AUTOSAR XML (schema 4-0-3)
standard types defined: Boolean, UInt16, UInt8
package /AUTOSAR_Platform/DataConstrs
  range DC_Boolean: raw 0..1
  range DC_UInt16: raw 0..65535
  range DC_UInt8: raw 0..255
package /PATAC/MSM/ComponentTypes
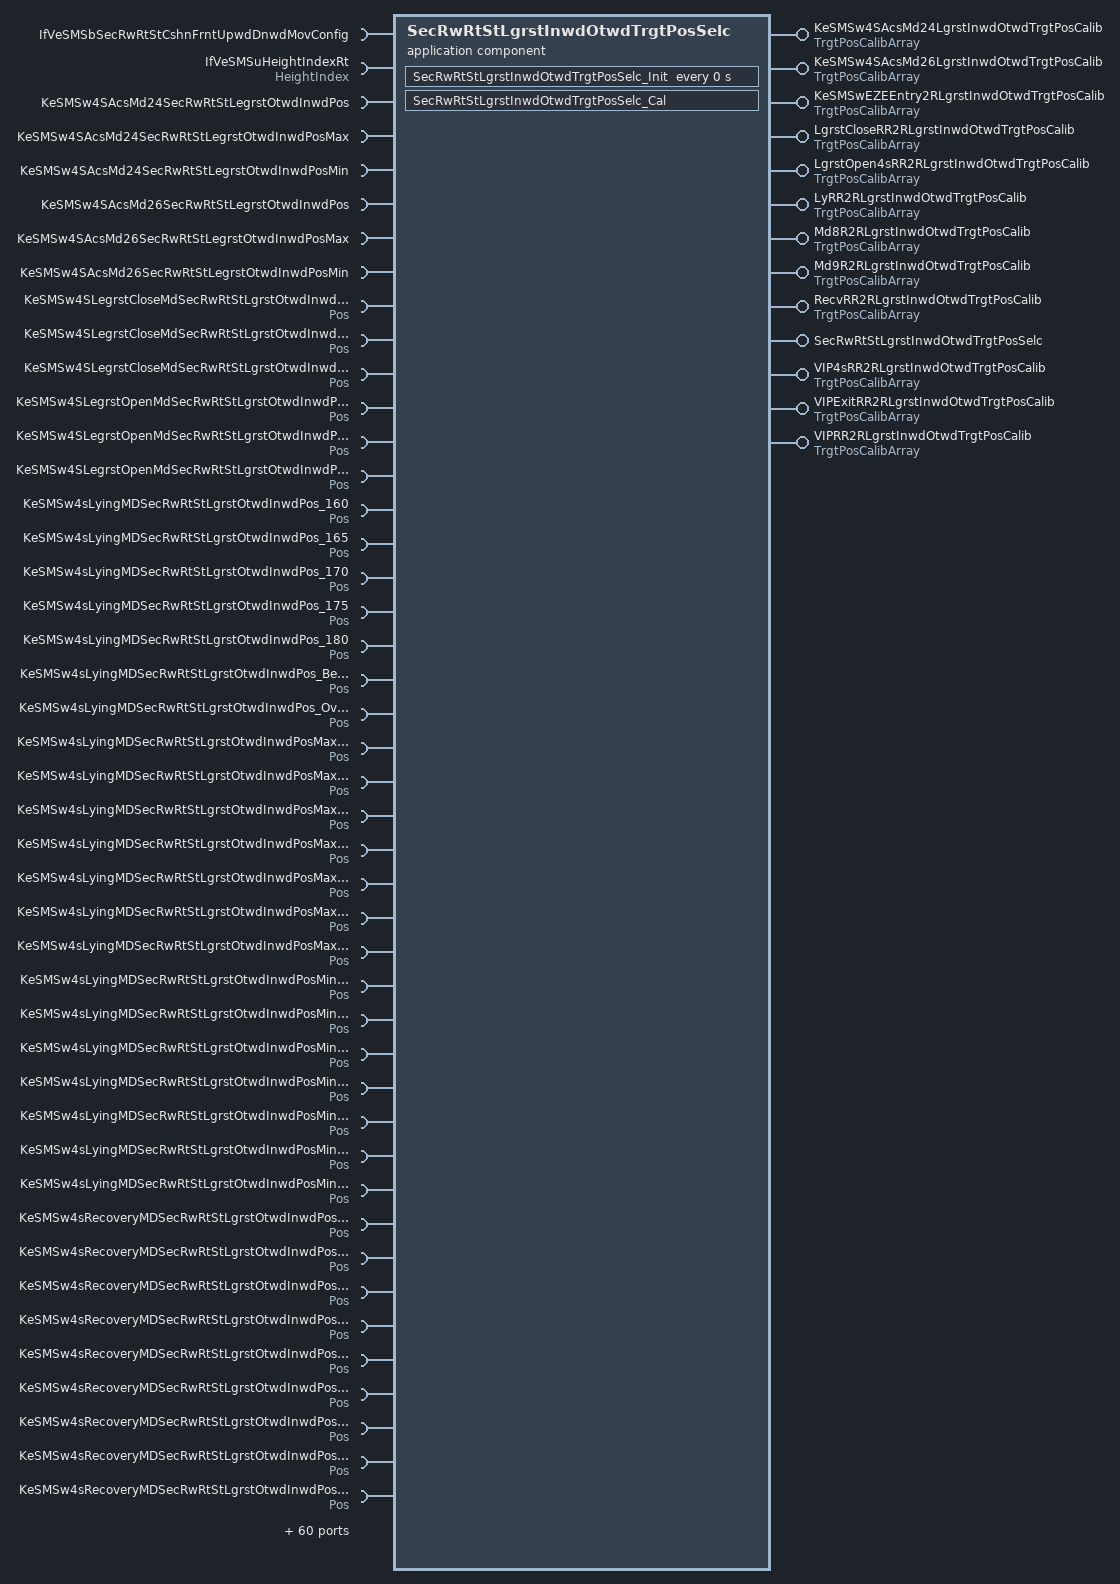
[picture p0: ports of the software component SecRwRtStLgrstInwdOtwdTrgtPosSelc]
  application sw component type SecRwRtStLgrstInwdOtwdTrgtPosSelc
    13 x provide port:
      KeSMSw4SAcsMd24LgrstInwdOtwdTrgtPosCalib: nonqueued-sender-com-spec{data-element=TrgtPosArray, init-value=[4095, 4095, 4095]}, provided-interface=TrgtPosCalibArray
      KeSMSw4SAcsMd26LgrstInwdOtwdTrgtPosCalib: nonqueued-sender-com-spec{data-element=TrgtPosArray, init-value=[4095, 4095, 4095]}, provided-interface=TrgtPosCalibArray
      KeSMSwEZEEntry2RLgrstInwdOtwdTrgtPosCalib: nonqueued-sender-com-spec{data-element=TrgtPosArray, init-value=[4095, 4095, 4095]}, provided-interface=TrgtPosCalibArray
      LgrstCloseRR2RLgrstInwdOtwdTrgtPosCalib: nonqueued-sender-com-spec{data-element=TrgtPosArray, init-value=[4095, 4095, 4095]}, provided-interface=TrgtPosCalibArray
      LgrstOpen4sRR2RLgrstInwdOtwdTrgtPosCalib: nonqueued-sender-com-spec{data-element=TrgtPosArray, init-value=[4095, 4095, 4095]}, provided-interface=TrgtPosCalibArray
      LyRR2RLgrstInwdOtwdTrgtPosCalib: nonqueued-sender-com-spec{data-element=TrgtPosArray, init-value=[4095, 4095, 4095]}, provided-interface=TrgtPosCalibArray
      Md8R2RLgrstInwdOtwdTrgtPosCalib: nonqueued-sender-com-spec{data-element=TrgtPosArray, init-value=[4095, 4095, 4095]}, provided-interface=TrgtPosCalibArray
      Md9R2RLgrstInwdOtwdTrgtPosCalib: nonqueued-sender-com-spec{data-element=TrgtPosArray, init-value=[4095, 4095, 4095]}, provided-interface=TrgtPosCalibArray
      RecvRR2RLgrstInwdOtwdTrgtPosCalib: nonqueued-sender-com-spec{data-element=TrgtPosArray, init-value=[4095, 4095, 4095]}, provided-interface=TrgtPosCalibArray
      SecRwRtStLgrstInwdOtwdTrgtPosSelc: server-com-spec{operation=Cal, queue-length=1}, provided-interface=SecRwRtStLgrstInwdOtwdTrgtPosSelc
      VIP4sRR2RLgrstInwdOtwdTrgtPosCalib: nonqueued-sender-com-spec{data-element=TrgtPosArray, init-value=[4095, 4095, 4095]}, provided-interface=TrgtPosCalibArray
      VIPExitRR2RLgrstInwdOtwdTrgtPosCalib: nonqueued-sender-com-spec{data-element=TrgtPosArray, init-value=[4095, 4095, 4095]}, provided-interface=TrgtPosCalibArray
      VIPRR2RLgrstInwdOtwdTrgtPosCalib: nonqueued-sender-com-spec{data-element=TrgtPosArray, init-value=[4095, 4095, 4095]}, provided-interface=TrgtPosCalibArray
    104 x require port:
      IfVeSMSbSecRwRtStCshnFrntUpwdDnwdMovConfig: nonqueued-receiver-com-spec{data-element=IfVeSMSbSecRwRtStCshnFrntUpwdDnwdMovConfig/Val, filter=data-filter-type=ALWAYS, init-value=0}, required-interface=IfVeSMSbSecRwRtStCshnFrntUpwdDnwdMovConfig
      IfVeSMSuHeightIndexRt: nonqueued-receiver-com-spec{data-element=HeightIndex/Val, filter=data-filter-type=ALWAYS, init-value=0}, required-interface=HeightIndex
      KeSMSw4SAcsMd24SecRwRtStLegrstOtwdInwdPos: parameter-require-com-spec{init-value=0, parameter=KeSMSw4SAcsMd24SecRwRtStLegrstOtwdInwdPos/Val}, required-interface=KeSMSw4SAcsMd24SecRwRtStLegrstOtwdInwdPos
      KeSMSw4SAcsMd24SecRwRtStLegrstOtwdInwdPosMax: parameter-require-com-spec{init-value=0, parameter=KeSMSw4SAcsMd24SecRwRtStLegrstOtwdInwdPosMax/Val}, required-interface=KeSMSw4SAcsMd24SecRwRtStLegrstOtwdInwdPosMax
      KeSMSw4SAcsMd24SecRwRtStLegrstOtwdInwdPosMin: parameter-require-com-spec{init-value=0, parameter=KeSMSw4SAcsMd24SecRwRtStLegrstOtwdInwdPosMin/Val}, required-interface=KeSMSw4SAcsMd24SecRwRtStLegrstOtwdInwdPosMin
      KeSMSw4SAcsMd26SecRwRtStLegrstOtwdInwdPos: parameter-require-com-spec{init-value=0, parameter=KeSMSw4SAcsMd26SecRwRtStLegrstOtwdInwdPos/Val}, required-interface=KeSMSw4SAcsMd26SecRwRtStLegrstOtwdInwdPos
      KeSMSw4SAcsMd26SecRwRtStLegrstOtwdInwdPosMax: parameter-require-com-spec{init-value=0, parameter=KeSMSw4SAcsMd26SecRwRtStLegrstOtwdInwdPosMax/Val}, required-interface=KeSMSw4SAcsMd26SecRwRtStLegrstOtwdInwdPosMax
      KeSMSw4SAcsMd26SecRwRtStLegrstOtwdInwdPosMin: parameter-require-com-spec{init-value=0, parameter=KeSMSw4SAcsMd26SecRwRtStLegrstOtwdInwdPosMin/Val}, required-interface=KeSMSw4SAcsMd26SecRwRtStLegrstOtwdInwdPosMin
      KeSMSw4SLegrstCloseMdSecRwRtStLgrstOtwdInwdPos: parameter-require-com-spec{init-value=0, parameter=Pos/Val}, required-interface=Pos
      KeSMSw4SLegrstCloseMdSecRwRtStLgrstOtwdInwdPosMax: parameter-require-com-spec{init-value=0, parameter=Pos/Val}, required-interface=Pos
      KeSMSw4SLegrstCloseMdSecRwRtStLgrstOtwdInwdPosMin: parameter-require-com-spec{init-value=0, parameter=Pos/Val}, required-interface=Pos
      KeSMSw4SLegrstOpenMdSecRwRtStLgrstOtwdInwdPos: parameter-require-com-spec{init-value=0, parameter=Pos/Val}, required-interface=Pos
      KeSMSw4SLegrstOpenMdSecRwRtStLgrstOtwdInwdPosMax: parameter-require-com-spec{init-value=0, parameter=Pos/Val}, required-interface=Pos
      KeSMSw4SLegrstOpenMdSecRwRtStLgrstOtwdInwdPosMin: parameter-require-com-spec{init-value=0, parameter=Pos/Val}, required-interface=Pos
      KeSMSw4sLyingMDSecRwRtStLgrstOtwdInwdPos_160: parameter-require-com-spec{init-value=0, parameter=Pos/Val}, required-interface=Pos
      KeSMSw4sLyingMDSecRwRtStLgrstOtwdInwdPos_165: parameter-require-com-spec{init-value=0, parameter=Pos/Val}, required-interface=Pos
      KeSMSw4sLyingMDSecRwRtStLgrstOtwdInwdPos_170: parameter-require-com-spec{init-value=0, parameter=Pos/Val}, required-interface=Pos
      KeSMSw4sLyingMDSecRwRtStLgrstOtwdInwdPos_175: parameter-require-com-spec{init-value=0, parameter=Pos/Val}, required-interface=Pos
      KeSMSw4sLyingMDSecRwRtStLgrstOtwdInwdPos_180: parameter-require-com-spec{init-value=0, parameter=Pos/Val}, required-interface=Pos
      KeSMSw4sLyingMDSecRwRtStLgrstOtwdInwdPos_Below160: parameter-require-com-spec{init-value=0, parameter=Pos/Val}, required-interface=Pos
      KeSMSw4sLyingMDSecRwRtStLgrstOtwdInwdPos_Over180: parameter-require-com-spec{init-value=0, parameter=Pos/Val}, required-interface=Pos
      KeSMSw4sLyingMDSecRwRtStLgrstOtwdInwdPosMax_160: parameter-require-com-spec{init-value=0, parameter=Pos/Val}, required-interface=Pos
      KeSMSw4sLyingMDSecRwRtStLgrstOtwdInwdPosMax_165: parameter-require-com-spec{init-value=0, parameter=Pos/Val}, required-interface=Pos
      KeSMSw4sLyingMDSecRwRtStLgrstOtwdInwdPosMax_170: parameter-require-com-spec{init-value=0, parameter=Pos/Val}, required-interface=Pos
      KeSMSw4sLyingMDSecRwRtStLgrstOtwdInwdPosMax_175: parameter-require-com-spec{init-value=0, parameter=Pos/Val}, required-interface=Pos
      KeSMSw4sLyingMDSecRwRtStLgrstOtwdInwdPosMax_180: parameter-require-com-spec{init-value=0, parameter=Pos/Val}, required-interface=Pos
      KeSMSw4sLyingMDSecRwRtStLgrstOtwdInwdPosMax_Below160: parameter-require-com-spec{init-value=0, parameter=Pos/Val}, required-interface=Pos
      KeSMSw4sLyingMDSecRwRtStLgrstOtwdInwdPosMax_Over180: parameter-require-com-spec{init-value=0, parameter=Pos/Val}, required-interface=Pos
      KeSMSw4sLyingMDSecRwRtStLgrstOtwdInwdPosMin_160: parameter-require-com-spec{init-value=0, parameter=Pos/Val}, required-interface=Pos
      KeSMSw4sLyingMDSecRwRtStLgrstOtwdInwdPosMin_165: parameter-require-com-spec{init-value=0, parameter=Pos/Val}, required-interface=Pos
      KeSMSw4sLyingMDSecRwRtStLgrstOtwdInwdPosMin_170: parameter-require-com-spec{init-value=0, parameter=Pos/Val}, required-interface=Pos
      KeSMSw4sLyingMDSecRwRtStLgrstOtwdInwdPosMin_175: parameter-require-com-spec{init-value=0, parameter=Pos/Val}, required-interface=Pos
      KeSMSw4sLyingMDSecRwRtStLgrstOtwdInwdPosMin_180: parameter-require-com-spec{init-value=0, parameter=Pos/Val}, required-interface=Pos
      KeSMSw4sLyingMDSecRwRtStLgrstOtwdInwdPosMin_Below160: parameter-require-com-spec{init-value=0, parameter=Pos/Val}, required-interface=Pos
      KeSMSw4sLyingMDSecRwRtStLgrstOtwdInwdPosMin_Over180: parameter-require-com-spec{init-value=0, parameter=Pos/Val}, required-interface=Pos
      KeSMSw4sRecoveryMDSecRwRtStLgrstOtwdInwdPos_160: parameter-require-com-spec{init-value=0, parameter=Pos/Val}, required-interface=Pos
      KeSMSw4sRecoveryMDSecRwRtStLgrstOtwdInwdPos_165: parameter-require-com-spec{init-value=0, parameter=Pos/Val}, required-interface=Pos
      KeSMSw4sRecoveryMDSecRwRtStLgrstOtwdInwdPos_170: parameter-require-com-spec{init-value=0, parameter=Pos/Val}, required-interface=Pos
      KeSMSw4sRecoveryMDSecRwRtStLgrstOtwdInwdPos_175: parameter-require-com-spec{init-value=0, parameter=Pos/Val}, required-interface=Pos
      KeSMSw4sRecoveryMDSecRwRtStLgrstOtwdInwdPos_180: parameter-require-com-spec{init-value=0, parameter=Pos/Val}, required-interface=Pos
      KeSMSw4sRecoveryMDSecRwRtStLgrstOtwdInwdPos_Below160: parameter-require-com-spec{init-value=0, parameter=Pos/Val}, required-interface=Pos
      KeSMSw4sRecoveryMDSecRwRtStLgrstOtwdInwdPos_Over180: parameter-require-com-spec{init-value=0, parameter=Pos/Val}, required-interface=Pos
      KeSMSw4sRecoveryMDSecRwRtStLgrstOtwdInwdPosMax_160: parameter-require-com-spec{init-value=0, parameter=Pos/Val}, required-interface=Pos
      KeSMSw4sRecoveryMDSecRwRtStLgrstOtwdInwdPosMax_165: parameter-require-com-spec{init-value=0, parameter=Pos/Val}, required-interface=Pos
      KeSMSw4sRecoveryMDSecRwRtStLgrstOtwdInwdPosMax_170: parameter-require-com-spec{init-value=0, parameter=Pos/Val}, required-interface=Pos
      KeSMSw4sRecoveryMDSecRwRtStLgrstOtwdInwdPosMax_175: parameter-require-com-spec{init-value=0, parameter=Pos/Val}, required-interface=Pos
      KeSMSw4sRecoveryMDSecRwRtStLgrstOtwdInwdPosMax_180: parameter-require-com-spec{init-value=0, parameter=Pos/Val}, required-interface=Pos
      KeSMSw4sRecoveryMDSecRwRtStLgrstOtwdInwdPosMax_Below160: parameter-require-com-spec{init-value=0, parameter=Pos/Val}, required-interface=Pos
      KeSMSw4sRecoveryMDSecRwRtStLgrstOtwdInwdPosMax_Over180: parameter-require-com-spec{init-value=0, parameter=Pos/Val}, required-interface=Pos
      KeSMSw4sRecoveryMDSecRwRtStLgrstOtwdInwdPosMin_160: parameter-require-com-spec{init-value=0, parameter=Pos/Val}, required-interface=Pos
      KeSMSw4sRecoveryMDSecRwRtStLgrstOtwdInwdPosMin_165: parameter-require-com-spec{init-value=0, parameter=Pos/Val}, required-interface=Pos
      KeSMSw4sRecoveryMDSecRwRtStLgrstOtwdInwdPosMin_170: parameter-require-com-spec{init-value=0, parameter=Pos/Val}, required-interface=Pos
      KeSMSw4sRecoveryMDSecRwRtStLgrstOtwdInwdPosMin_175: parameter-require-com-spec{init-value=0, parameter=Pos/Val}, required-interface=Pos
      KeSMSw4sRecoveryMDSecRwRtStLgrstOtwdInwdPosMin_180: parameter-require-com-spec{init-value=0, parameter=Pos/Val}, required-interface=Pos
      KeSMSw4sRecoveryMDSecRwRtStLgrstOtwdInwdPosMin_Below160: parameter-require-com-spec{init-value=0, parameter=Pos/Val}, required-interface=Pos
      KeSMSw4sRecoveryMDSecRwRtStLgrstOtwdInwdPosMin_Over180: parameter-require-com-spec{init-value=0, parameter=Pos/Val}, required-interface=Pos
      KeSMSw4sVIPMDSecRwRtStLgrstOtwdInwdPos_160: parameter-require-com-spec{init-value=0, parameter=Pos/Val}, required-interface=Pos
      KeSMSw4sVIPMDSecRwRtStLgrstOtwdInwdPos_165: parameter-require-com-spec{init-value=0, parameter=Pos/Val}, required-interface=Pos
      KeSMSw4sVIPMDSecRwRtStLgrstOtwdInwdPos_170: parameter-require-com-spec{init-value=0, parameter=Pos/Val}, required-interface=Pos
      KeSMSw4sVIPMDSecRwRtStLgrstOtwdInwdPos_175: parameter-require-com-spec{init-value=0, parameter=Pos/Val}, required-interface=Pos
      KeSMSw4sVIPMDSecRwRtStLgrstOtwdInwdPos_180: parameter-require-com-spec{init-value=0, parameter=Pos/Val}, required-interface=Pos
      KeSMSw4sVIPMDSecRwRtStLgrstOtwdInwdPos_Below160: parameter-require-com-spec{init-value=0, parameter=Pos/Val}, required-interface=Pos
      KeSMSw4sVIPMDSecRwRtStLgrstOtwdInwdPos_Over180: parameter-require-com-spec{init-value=0, parameter=Pos/Val}, required-interface=Pos
      KeSMSw4sVIPMDSecRwRtStLgrstOtwdInwdPosMax_160: parameter-require-com-spec{init-value=0, parameter=Pos/Val}, required-interface=Pos
      KeSMSw4sVIPMDSecRwRtStLgrstOtwdInwdPosMax_165: parameter-require-com-spec{init-value=0, parameter=Pos/Val}, required-interface=Pos
      KeSMSw4sVIPMDSecRwRtStLgrstOtwdInwdPosMax_170: parameter-require-com-spec{init-value=0, parameter=Pos/Val}, required-interface=Pos
      KeSMSw4sVIPMDSecRwRtStLgrstOtwdInwdPosMax_175: parameter-require-com-spec{init-value=0, parameter=Pos/Val}, required-interface=Pos
      KeSMSw4sVIPMDSecRwRtStLgrstOtwdInwdPosMax_180: parameter-require-com-spec{init-value=0, parameter=Pos/Val}, required-interface=Pos
      KeSMSw4sVIPMDSecRwRtStLgrstOtwdInwdPosMax_Below160: parameter-require-com-spec{init-value=0, parameter=Pos/Val}, required-interface=Pos
      KeSMSw4sVIPMDSecRwRtStLgrstOtwdInwdPosMax_Over180: parameter-require-com-spec{init-value=0, parameter=Pos/Val}, required-interface=Pos
      KeSMSw4sVIPMDSecRwRtStLgrstOtwdInwdPosMin_160: parameter-require-com-spec{init-value=0, parameter=Pos/Val}, required-interface=Pos
      KeSMSw4sVIPMDSecRwRtStLgrstOtwdInwdPosMin_165: parameter-require-com-spec{init-value=0, parameter=Pos/Val}, required-interface=Pos
      KeSMSw4sVIPMDSecRwRtStLgrstOtwdInwdPosMin_170: parameter-require-com-spec{init-value=0, parameter=Pos/Val}, required-interface=Pos
      KeSMSw4sVIPMDSecRwRtStLgrstOtwdInwdPosMin_175: parameter-require-com-spec{init-value=0, parameter=Pos/Val}, required-interface=Pos
      KeSMSw4sVIPMDSecRwRtStLgrstOtwdInwdPosMin_180: parameter-require-com-spec{init-value=0, parameter=Pos/Val}, required-interface=Pos
      KeSMSw4sVIPMDSecRwRtStLgrstOtwdInwdPosMin_Below160: parameter-require-com-spec{init-value=0, parameter=Pos/Val}, required-interface=Pos
      KeSMSw4sVIPMDSecRwRtStLgrstOtwdInwdPosMin_Over180: parameter-require-com-spec{init-value=0, parameter=Pos/Val}, required-interface=Pos
      KeSMSw6sAcsEntrySecRwRtStLgrstInwdOtwdPos: parameter-require-com-spec{init-value=4095, parameter=Pos/Val}, required-interface=Pos
      KeSMSw6sAcsEntrySecRwRtStLgrstInwdOtwdPosMax: parameter-require-com-spec{init-value=4095, parameter=Pos/Val}, required-interface=Pos
      KeSMSw6sAcsEntrySecRwRtStLgrstInwdOtwdPosMin: parameter-require-com-spec{init-value=4095, parameter=Pos/Val}, required-interface=Pos
      KeSMSw6sRecoveryMdSecRwRtStLgrstInwdOtwdPos: parameter-require-com-spec{init-value=4095, parameter=Pos/Val}, required-interface=Pos
      KeSMSw6sRecoveryMdSecRwRtStLgrstInwdOtwdPosMax: parameter-require-com-spec{init-value=4095, parameter=Pos/Val}, required-interface=Pos
      KeSMSw6sRecoveryMdSecRwRtStLgrstInwdOtwdPosMin: parameter-require-com-spec{init-value=4095, parameter=Pos/Val}, required-interface=Pos
      KeSMSw6SVIPMdSecRwRtStLgrstInwdOtwdPos: parameter-require-com-spec{init-value=4095, parameter=Pos/Val}, required-interface=Pos
      KeSMSw6SVIPMdSecRwRtStLgrstInwdOtwdPosMax: parameter-require-com-spec{init-value=4095, parameter=Pos/Val}, required-interface=Pos
      KeSMSw6SVIPMdSecRwRtStLgrstInwdOtwdPosMin: parameter-require-com-spec{init-value=4095, parameter=Pos/Val}, required-interface=Pos
      KeSMSwAcsEntrySecRwRtStLgrstInwdOtwdPos: parameter-require-com-spec{init-value=4095, parameter=Pos/Val}, required-interface=Pos
      KeSMSwAcsEntrySecRwRtStLgrstInwdOtwdPosMax: parameter-require-com-spec{init-value=4095, parameter=Pos/Val}, required-interface=Pos
      KeSMSwAcsEntrySecRwRtStLgrstInwdOtwdPosMin: parameter-require-com-spec{init-value=4095, parameter=Pos/Val}, required-interface=Pos
      KeSMSwAcsMd8SecRwRtStLgrstInwdOtwdPos: parameter-require-com-spec{init-value=4095, parameter=Pos/Val}, required-interface=Pos
      KeSMSwAcsMd8SecRwRtStLgrstInwdOtwdPosMax: parameter-require-com-spec{init-value=4095, parameter=Pos/Val}, required-interface=Pos
      KeSMSwAcsMd8SecRwRtStLgrstInwdOtwdPosMin: parameter-require-com-spec{init-value=4095, parameter=Pos/Val}, required-interface=Pos
      KeSMSwAcsMd9SecRwRtStLgrstInwdOtwdPos: parameter-require-com-spec{init-value=4095, parameter=Pos/Val}, required-interface=Pos
      KeSMSwAcsMd9SecRwRtStLgrstInwdOtwdPosMax: parameter-require-com-spec{init-value=4095, parameter=Pos/Val}, required-interface=Pos
      KeSMSwAcsMd9SecRwRtStLgrstInwdOtwdPosMin: parameter-require-com-spec{init-value=4095, parameter=Pos/Val}, required-interface=Pos
      KeSMSwRecoveryMdSecRwRtStLgrstInwdOtwdPos: parameter-require-com-spec{init-value=4095, parameter=Pos/Val}, required-interface=Pos
      KeSMSwRecoveryMdSecRwRtStLgrstInwdOtwdPosMax: parameter-require-com-spec{init-value=4095, parameter=Pos/Val}, required-interface=Pos
      KeSMSwRecoveryMdSecRwRtStLgrstInwdOtwdPosMin: parameter-require-com-spec{init-value=4095, parameter=Pos/Val}, required-interface=Pos
      KeSMSwVIPMdSecRwRtStLgrstInwdOtwdPos: parameter-require-com-spec{init-value=4095, parameter=Pos/Val}, required-interface=Pos
      KeSMSwVIPMdSecRwRtStLgrstInwdOtwdPosMax: parameter-require-com-spec{init-value=4095, parameter=Pos/Val}, required-interface=Pos
      KeSMSwVIPMdSecRwRtStLgrstInwdOtwdPosMin: parameter-require-com-spec{init-value=4095, parameter=Pos/Val}, required-interface=Pos
      StNumFlg: required-interface=StNumFlg
        required-com-specs:
          data-element=Is4s, filter=data-filter-type=ALWAYS, init-value=0
          data-element=Is6s, filter=data-filter-type=ALWAYS, init-value=0
          data-element=Is6s7s, filter=data-filter-type=ALWAYS, init-value=0
          data-element=Is7s, filter=data-filter-type=ALWAYS, init-value=0
      VIPR557TrgtPos: required-com-specs=[VIPR557TrgtPos/Get, VIPR557TrgtPos/Set], required-interface=VIPR557TrgtPos
      VIPRExit557TrgtPos: required-com-specs=[VIPRExit557TrgtPos/Get, VIPRExit557TrgtPos/Set], required-interface=VIPRExit557TrgtPos
    behavior SecRwRtStLgrstInwdOtwdTrgtPosSelc_InternalBehavior
      operation invoked event OIT_SecRwRtStLgrstInwdOtwdTrgtPosSelc_Cal_SecRwRtStLgrstInwdOtwdTrgtPosSelc_Cal: start-on-event=SecRwRtStLgrstInwdOtwdTrgtPosSelc_Cal, operation=SecRwRtStLgrstInwdOtwdTrgtPosSelc.Cal
      timing event SecRwRtStLgrstInwdOtwdTrgtPosSelc_InitEvent: start-on-event=SecRwRtStLgrstInwdOtwdTrgtPosSelc_Init, period=0
      runnable SecRwRtStLgrstInwdOtwdTrgtPosSelc_Cal
        data-receive-point-by-arguments:
          6 x access:
            REC_IfVeSMSbSecRwRtStCshnFrntUpwdDnwdMovConfig_Val: accessed-variable=IfVeSMSbSecRwRtStCshnFrntUpwdDnwdMovConfig.Val
            REC_IfVeSMSuHeightIndexRt_Val: accessed-variable=IfVeSMSuHeightIndexRt.Val
            REC_StNumFlg_Is4s: accessed-variable=StNumFlg.Is4s
            REC_StNumFlg_Is6s: accessed-variable=StNumFlg.Is6s
            REC_StNumFlg_Is6s7s: accessed-variable=StNumFlg.Is6s7s
            REC_StNumFlg_Is7s: accessed-variable=StNumFlg.Is7s
        data-send-points:
          12 x access:
            SEND_KeSMSw4SAcsMd24LgrstInwdOtwdTrgtPosCalib_TrgtPosArray: accessed-variable=KeSMSw4SAcsMd24LgrstInwdOtwdTrgtPosCalib.TrgtPosArray
            SEND_KeSMSw4SAcsMd26LgrstInwdOtwdTrgtPosCalib_TrgtPosArray: accessed-variable=KeSMSw4SAcsMd26LgrstInwdOtwdTrgtPosCalib.TrgtPosArray
            SEND_KeSMSwEZEEntry2RLgrstInwdOtwdTrgtPosCalib_TrgtPosArray: accessed-variable=KeSMSwEZEEntry2RLgrstInwdOtwdTrgtPosCalib.TrgtPosArray
            SEND_LgrstCloseRR2RLgrstInwdOtwdTrgtPosCalib_TrgtPosArray: accessed-variable=LgrstCloseRR2RLgrstInwdOtwdTrgtPosCalib.TrgtPosArray
            SEND_LgrstOpen4sRR2RLgrstInwdOtwdTrgtPosCalib_TrgtPosArray: accessed-variable=LgrstOpen4sRR2RLgrstInwdOtwdTrgtPosCalib.TrgtPosArray
            SEND_LyRR2RLgrstInwdOtwdTrgtPosCalib_TrgtPosArray: accessed-variable=LyRR2RLgrstInwdOtwdTrgtPosCalib.TrgtPosArray
            SEND_Md8R2RLgrstInwdOtwdTrgtPosCalib_TrgtPosArray: accessed-variable=Md8R2RLgrstInwdOtwdTrgtPosCalib.TrgtPosArray
            SEND_Md9R2RLgrstInwdOtwdTrgtPosCalib_TrgtPosArray: accessed-variable=Md9R2RLgrstInwdOtwdTrgtPosCalib.TrgtPosArray
            SEND_RecvRR2RLgrstInwdOtwdTrgtPosCalib_TrgtPosArray: accessed-variable=RecvRR2RLgrstInwdOtwdTrgtPosCalib.TrgtPosArray
            SEND_VIP4sRR2RLgrstInwdOtwdTrgtPosCalib_TrgtPosArray: accessed-variable=VIP4sRR2RLgrstInwdOtwdTrgtPosCalib.TrgtPosArray
            SEND_VIPExitRR2RLgrstInwdOtwdTrgtPosCalib_TrgtPosArray: accessed-variable=VIPExitRR2RLgrstInwdOtwdTrgtPosCalib.TrgtPosArray
            SEND_VIPRR2RLgrstInwdOtwdTrgtPosCalib_TrgtPosArray: accessed-variable=VIPRR2RLgrstInwdOtwdTrgtPosCalib.TrgtPosArray
        99 x parameter access:
          PA_KeSMSw4SAcsMd24SecRwRtStLegrstOtwdInwdPos_Val: accessed-parameter=KeSMSw4SAcsMd24SecRwRtStLegrstOtwdInwdPos.Val
          PA_KeSMSw4SAcsMd24SecRwRtStLegrstOtwdInwdPosMax_Val: accessed-parameter=KeSMSw4SAcsMd24SecRwRtStLegrstOtwdInwdPosMax.Val
          PA_KeSMSw4SAcsMd24SecRwRtStLegrstOtwdInwdPosMin_Val: accessed-parameter=KeSMSw4SAcsMd24SecRwRtStLegrstOtwdInwdPosMin.Val
          PA_KeSMSw4SAcsMd26SecRwRtStLegrstOtwdInwdPos_Val: accessed-parameter=KeSMSw4SAcsMd26SecRwRtStLegrstOtwdInwdPos.Val
          PA_KeSMSw4SAcsMd26SecRwRtStLegrstOtwdInwdPosMax_Val: accessed-parameter=KeSMSw4SAcsMd26SecRwRtStLegrstOtwdInwdPosMax.Val
          PA_KeSMSw4SAcsMd26SecRwRtStLegrstOtwdInwdPosMin_Val: accessed-parameter=KeSMSw4SAcsMd26SecRwRtStLegrstOtwdInwdPosMin.Val
          PA_KeSMSw4SLegrstCloseMdSecRwRtStLgrstOtwdInwdPos_Val: accessed-parameter=KeSMSw4SLegrstCloseMdSecRwRtStLgrstOtwdInwdPos.Val
          PA_KeSMSw4SLegrstCloseMdSecRwRtStLgrstOtwdInwdPosMax_Val: accessed-parameter=KeSMSw4SLegrstCloseMdSecRwRtStLgrstOtwdInwdPosMax.Val
          PA_KeSMSw4SLegrstCloseMdSecRwRtStLgrstOtwdInwdPosMin_Val: accessed-parameter=KeSMSw4SLegrstCloseMdSecRwRtStLgrstOtwdInwdPosMin.Val
          PA_KeSMSw4SLegrstOpenMdSecRwRtStLgrstOtwdInwdPos_Val: accessed-parameter=KeSMSw4SLegrstOpenMdSecRwRtStLgrstOtwdInwdPos.Val
          PA_KeSMSw4SLegrstOpenMdSecRwRtStLgrstOtwdInwdPosMax_Val: accessed-parameter=KeSMSw4SLegrstOpenMdSecRwRtStLgrstOtwdInwdPosMax.Val
          PA_KeSMSw4SLegrstOpenMdSecRwRtStLgrstOtwdInwdPosMin_Val: accessed-parameter=KeSMSw4SLegrstOpenMdSecRwRtStLgrstOtwdInwdPosMin.Val
          PA_KeSMSw4sLyingMDSecRwRtStLgrstOtwdInwdPos_160_Val: accessed-parameter=KeSMSw4sLyingMDSecRwRtStLgrstOtwdInwdPos_160.Val
          PA_KeSMSw4sLyingMDSecRwRtStLgrstOtwdInwdPos_165_Val: accessed-parameter=KeSMSw4sLyingMDSecRwRtStLgrstOtwdInwdPos_165.Val
          PA_KeSMSw4sLyingMDSecRwRtStLgrstOtwdInwdPos_170_Val: accessed-parameter=KeSMSw4sLyingMDSecRwRtStLgrstOtwdInwdPos_170.Val
          PA_KeSMSw4sLyingMDSecRwRtStLgrstOtwdInwdPos_175_Val: accessed-parameter=KeSMSw4sLyingMDSecRwRtStLgrstOtwdInwdPos_175.Val
          PA_KeSMSw4sLyingMDSecRwRtStLgrstOtwdInwdPos_180_Val: accessed-parameter=KeSMSw4sLyingMDSecRwRtStLgrstOtwdInwdPos_180.Val
          PA_KeSMSw4sLyingMDSecRwRtStLgrstOtwdInwdPos_Below160_Val: accessed-parameter=KeSMSw4sLyingMDSecRwRtStLgrstOtwdInwdPos_Below160.Val
          PA_KeSMSw4sLyingMDSecRwRtStLgrstOtwdInwdPos_Over180_Val: accessed-parameter=KeSMSw4sLyingMDSecRwRtStLgrstOtwdInwdPos_Over180.Val
          PA_KeSMSw4sLyingMDSecRwRtStLgrstOtwdInwdPosMax_160_Val: accessed-parameter=KeSMSw4sLyingMDSecRwRtStLgrstOtwdInwdPosMax_160.Val
          PA_KeSMSw4sLyingMDSecRwRtStLgrstOtwdInwdPosMax_165_Val: accessed-parameter=KeSMSw4sLyingMDSecRwRtStLgrstOtwdInwdPosMax_165.Val
          PA_KeSMSw4sLyingMDSecRwRtStLgrstOtwdInwdPosMax_170_Val: accessed-parameter=KeSMSw4sLyingMDSecRwRtStLgrstOtwdInwdPosMax_170.Val
          PA_KeSMSw4sLyingMDSecRwRtStLgrstOtwdInwdPosMax_175_Val: accessed-parameter=KeSMSw4sLyingMDSecRwRtStLgrstOtwdInwdPosMax_175.Val
          PA_KeSMSw4sLyingMDSecRwRtStLgrstOtwdInwdPosMax_180_Val: accessed-parameter=KeSMSw4sLyingMDSecRwRtStLgrstOtwdInwdPosMax_180.Val
          PA_KeSMSw4sLyingMDSecRwRtStLgrstOtwdInwdPosMax_Below160_Val: accessed-parameter=KeSMSw4sLyingMDSecRwRtStLgrstOtwdInwdPosMax_Below160.Val
          PA_KeSMSw4sLyingMDSecRwRtStLgrstOtwdInwdPosMax_Over180_Val: accessed-parameter=KeSMSw4sLyingMDSecRwRtStLgrstOtwdInwdPosMax_Over180.Val
          PA_KeSMSw4sLyingMDSecRwRtStLgrstOtwdInwdPosMin_160_Val: accessed-parameter=KeSMSw4sLyingMDSecRwRtStLgrstOtwdInwdPosMin_160.Val
          PA_KeSMSw4sLyingMDSecRwRtStLgrstOtwdInwdPosMin_165_Val: accessed-parameter=KeSMSw4sLyingMDSecRwRtStLgrstOtwdInwdPosMin_165.Val
          PA_KeSMSw4sLyingMDSecRwRtStLgrstOtwdInwdPosMin_170_Val: accessed-parameter=KeSMSw4sLyingMDSecRwRtStLgrstOtwdInwdPosMin_170.Val
          PA_KeSMSw4sLyingMDSecRwRtStLgrstOtwdInwdPosMin_175_Val: accessed-parameter=KeSMSw4sLyingMDSecRwRtStLgrstOtwdInwdPosMin_175.Val
          PA_KeSMSw4sLyingMDSecRwRtStLgrstOtwdInwdPosMin_180_Val: accessed-parameter=KeSMSw4sLyingMDSecRwRtStLgrstOtwdInwdPosMin_180.Val
          PA_KeSMSw4sLyingMDSecRwRtStLgrstOtwdInwdPosMin_Below160_Val: accessed-parameter=KeSMSw4sLyingMDSecRwRtStLgrstOtwdInwdPosMin_Below160.Val
          PA_KeSMSw4sLyingMDSecRwRtStLgrstOtwdInwdPosMin_Over180_Val: accessed-parameter=KeSMSw4sLyingMDSecRwRtStLgrstOtwdInwdPosMin_Over180.Val
          PA_KeSMSw4sRecoveryMDSecRwRtStLgrstOtwdInwdPos_160_Val: accessed-parameter=KeSMSw4sRecoveryMDSecRwRtStLgrstOtwdInwdPos_160.Val
          PA_KeSMSw4sRecoveryMDSecRwRtStLgrstOtwdInwdPos_165_Val: accessed-parameter=KeSMSw4sRecoveryMDSecRwRtStLgrstOtwdInwdPos_165.Val
          PA_KeSMSw4sRecoveryMDSecRwRtStLgrstOtwdInwdPos_170_Val: accessed-parameter=KeSMSw4sRecoveryMDSecRwRtStLgrstOtwdInwdPos_170.Val
          PA_KeSMSw4sRecoveryMDSecRwRtStLgrstOtwdInwdPos_175_Val: accessed-parameter=KeSMSw4sRecoveryMDSecRwRtStLgrstOtwdInwdPos_175.Val
          PA_KeSMSw4sRecoveryMDSecRwRtStLgrstOtwdInwdPos_180_Val: accessed-parameter=KeSMSw4sRecoveryMDSecRwRtStLgrstOtwdInwdPos_180.Val
          PA_KeSMSw4sRecoveryMDSecRwRtStLgrstOtwdInwdPos_Below160_Val: accessed-parameter=KeSMSw4sRecoveryMDSecRwRtStLgrstOtwdInwdPos_Below160.Val
          PA_KeSMSw4sRecoveryMDSecRwRtStLgrstOtwdInwdPos_Over180_Val: accessed-parameter=KeSMSw4sRecoveryMDSecRwRtStLgrstOtwdInwdPos_Over180.Val
          PA_KeSMSw4sRecoveryMDSecRwRtStLgrstOtwdInwdPosMax_160_Val: accessed-parameter=KeSMSw4sRecoveryMDSecRwRtStLgrstOtwdInwdPosMax_160.Val
          PA_KeSMSw4sRecoveryMDSecRwRtStLgrstOtwdInwdPosMax_165_Val: accessed-parameter=KeSMSw4sRecoveryMDSecRwRtStLgrstOtwdInwdPosMax_165.Val
          PA_KeSMSw4sRecoveryMDSecRwRtStLgrstOtwdInwdPosMax_170_Val: accessed-parameter=KeSMSw4sRecoveryMDSecRwRtStLgrstOtwdInwdPosMax_170.Val
          PA_KeSMSw4sRecoveryMDSecRwRtStLgrstOtwdInwdPosMax_175_Val: accessed-parameter=KeSMSw4sRecoveryMDSecRwRtStLgrstOtwdInwdPosMax_175.Val
          PA_KeSMSw4sRecoveryMDSecRwRtStLgrstOtwdInwdPosMax_180_Val: accessed-parameter=KeSMSw4sRecoveryMDSecRwRtStLgrstOtwdInwdPosMax_180.Val
          PA_KeSMSw4sRecoveryMDSecRwRtStLgrstOtwdInwdPosMax_Below160_Val: accessed-parameter=KeSMSw4sRecoveryMDSecRwRtStLgrstOtwdInwdPosMax_Below160.Val
          PA_KeSMSw4sRecoveryMDSecRwRtStLgrstOtwdInwdPosMax_Over180_Val: accessed-parameter=KeSMSw4sRecoveryMDSecRwRtStLgrstOtwdInwdPosMax_Over180.Val
          PA_KeSMSw4sRecoveryMDSecRwRtStLgrstOtwdInwdPosMin_160_Val: accessed-parameter=KeSMSw4sRecoveryMDSecRwRtStLgrstOtwdInwdPosMin_160.Val
          PA_KeSMSw4sRecoveryMDSecRwRtStLgrstOtwdInwdPosMin_165_Val: accessed-parameter=KeSMSw4sRecoveryMDSecRwRtStLgrstOtwdInwdPosMin_165.Val
          PA_KeSMSw4sRecoveryMDSecRwRtStLgrstOtwdInwdPosMin_170_Val: accessed-parameter=KeSMSw4sRecoveryMDSecRwRtStLgrstOtwdInwdPosMin_170.Val
          PA_KeSMSw4sRecoveryMDSecRwRtStLgrstOtwdInwdPosMin_175_Val: accessed-parameter=KeSMSw4sRecoveryMDSecRwRtStLgrstOtwdInwdPosMin_175.Val
          PA_KeSMSw4sRecoveryMDSecRwRtStLgrstOtwdInwdPosMin_180_Val: accessed-parameter=KeSMSw4sRecoveryMDSecRwRtStLgrstOtwdInwdPosMin_180.Val
          PA_KeSMSw4sRecoveryMDSecRwRtStLgrstOtwdInwdPosMin_Below160_Val: accessed-parameter=KeSMSw4sRecoveryMDSecRwRtStLgrstOtwdInwdPosMin_Below160.Val
          PA_KeSMSw4sRecoveryMDSecRwRtStLgrstOtwdInwdPosMin_Over180_Val: accessed-parameter=KeSMSw4sRecoveryMDSecRwRtStLgrstOtwdInwdPosMin_Over180.Val
          PA_KeSMSw4sVIPMDSecRwRtStLgrstOtwdInwdPos_160_Val: accessed-parameter=KeSMSw4sVIPMDSecRwRtStLgrstOtwdInwdPos_160.Val
          PA_KeSMSw4sVIPMDSecRwRtStLgrstOtwdInwdPos_165_Val: accessed-parameter=KeSMSw4sVIPMDSecRwRtStLgrstOtwdInwdPos_165.Val
          PA_KeSMSw4sVIPMDSecRwRtStLgrstOtwdInwdPos_170_Val: accessed-parameter=KeSMSw4sVIPMDSecRwRtStLgrstOtwdInwdPos_170.Val
          PA_KeSMSw4sVIPMDSecRwRtStLgrstOtwdInwdPos_175_Val: accessed-parameter=KeSMSw4sVIPMDSecRwRtStLgrstOtwdInwdPos_175.Val
          PA_KeSMSw4sVIPMDSecRwRtStLgrstOtwdInwdPos_180_Val: accessed-parameter=KeSMSw4sVIPMDSecRwRtStLgrstOtwdInwdPos_180.Val
          PA_KeSMSw4sVIPMDSecRwRtStLgrstOtwdInwdPos_Below160_Val: accessed-parameter=KeSMSw4sVIPMDSecRwRtStLgrstOtwdInwdPos_Below160.Val
          PA_KeSMSw4sVIPMDSecRwRtStLgrstOtwdInwdPos_Over180_Val: accessed-parameter=KeSMSw4sVIPMDSecRwRtStLgrstOtwdInwdPos_Over180.Val
          PA_KeSMSw4sVIPMDSecRwRtStLgrstOtwdInwdPosMax_160_Val: accessed-parameter=KeSMSw4sVIPMDSecRwRtStLgrstOtwdInwdPosMax_160.Val
          PA_KeSMSw4sVIPMDSecRwRtStLgrstOtwdInwdPosMax_165_Val: accessed-parameter=KeSMSw4sVIPMDSecRwRtStLgrstOtwdInwdPosMax_165.Val
          PA_KeSMSw4sVIPMDSecRwRtStLgrstOtwdInwdPosMax_170_Val: accessed-parameter=KeSMSw4sVIPMDSecRwRtStLgrstOtwdInwdPosMax_170.Val
          PA_KeSMSw4sVIPMDSecRwRtStLgrstOtwdInwdPosMax_175_Val: accessed-parameter=KeSMSw4sVIPMDSecRwRtStLgrstOtwdInwdPosMax_175.Val
          PA_KeSMSw4sVIPMDSecRwRtStLgrstOtwdInwdPosMax_180_Val: accessed-parameter=KeSMSw4sVIPMDSecRwRtStLgrstOtwdInwdPosMax_180.Val
          PA_KeSMSw4sVIPMDSecRwRtStLgrstOtwdInwdPosMax_Below160_Val: accessed-parameter=KeSMSw4sVIPMDSecRwRtStLgrstOtwdInwdPosMax_Below160.Val
          PA_KeSMSw4sVIPMDSecRwRtStLgrstOtwdInwdPosMax_Over180_Val: accessed-parameter=KeSMSw4sVIPMDSecRwRtStLgrstOtwdInwdPosMax_Over180.Val
          PA_KeSMSw4sVIPMDSecRwRtStLgrstOtwdInwdPosMin_160_Val: accessed-parameter=KeSMSw4sVIPMDSecRwRtStLgrstOtwdInwdPosMin_160.Val
          PA_KeSMSw4sVIPMDSecRwRtStLgrstOtwdInwdPosMin_165_Val: accessed-parameter=KeSMSw4sVIPMDSecRwRtStLgrstOtwdInwdPosMin_165.Val
          PA_KeSMSw4sVIPMDSecRwRtStLgrstOtwdInwdPosMin_170_Val: accessed-parameter=KeSMSw4sVIPMDSecRwRtStLgrstOtwdInwdPosMin_170.Val
          PA_KeSMSw4sVIPMDSecRwRtStLgrstOtwdInwdPosMin_175_Val: accessed-parameter=KeSMSw4sVIPMDSecRwRtStLgrstOtwdInwdPosMin_175.Val
          PA_KeSMSw4sVIPMDSecRwRtStLgrstOtwdInwdPosMin_180_Val: accessed-parameter=KeSMSw4sVIPMDSecRwRtStLgrstOtwdInwdPosMin_180.Val
          PA_KeSMSw4sVIPMDSecRwRtStLgrstOtwdInwdPosMin_Below160_Val: accessed-parameter=KeSMSw4sVIPMDSecRwRtStLgrstOtwdInwdPosMin_Below160.Val
          PA_KeSMSw4sVIPMDSecRwRtStLgrstOtwdInwdPosMin_Over180_Val: accessed-parameter=KeSMSw4sVIPMDSecRwRtStLgrstOtwdInwdPosMin_Over180.Val
          PA_KeSMSw6sAcsEntrySecRwRtStLgrstInwdOtwdPos_Val: accessed-parameter=KeSMSw6sAcsEntrySecRwRtStLgrstInwdOtwdPos.Val
          PA_KeSMSw6sAcsEntrySecRwRtStLgrstInwdOtwdPosMax_Val: accessed-parameter=KeSMSw6sAcsEntrySecRwRtStLgrstInwdOtwdPosMax.Val
          PA_KeSMSw6sAcsEntrySecRwRtStLgrstInwdOtwdPosMin_Val: accessed-parameter=KeSMSw6sAcsEntrySecRwRtStLgrstInwdOtwdPosMin.Val
          PA_KeSMSw6sRecoveryMdSecRwRtStLgrstInwdOtwdPos_Val: accessed-parameter=KeSMSw6sRecoveryMdSecRwRtStLgrstInwdOtwdPos.Val
          PA_KeSMSw6sRecoveryMdSecRwRtStLgrstInwdOtwdPosMax_Val: accessed-parameter=KeSMSw6sRecoveryMdSecRwRtStLgrstInwdOtwdPosMax.Val
          PA_KeSMSw6sRecoveryMdSecRwRtStLgrstInwdOtwdPosMin_Val: accessed-parameter=KeSMSw6sRecoveryMdSecRwRtStLgrstInwdOtwdPosMin.Val
          PA_KeSMSw6SVIPMdSecRwRtStLgrstInwdOtwdPos_Val: accessed-parameter=KeSMSw6SVIPMdSecRwRtStLgrstInwdOtwdPos.Val
          PA_KeSMSw6SVIPMdSecRwRtStLgrstInwdOtwdPosMax_Val: accessed-parameter=KeSMSw6SVIPMdSecRwRtStLgrstInwdOtwdPosMax.Val
          PA_KeSMSw6SVIPMdSecRwRtStLgrstInwdOtwdPosMin_Val: accessed-parameter=KeSMSw6SVIPMdSecRwRtStLgrstInwdOtwdPosMin.Val
          PA_KeSMSwAcsEntrySecRwRtStLgrstInwdOtwdPos_Val: accessed-parameter=KeSMSwAcsEntrySecRwRtStLgrstInwdOtwdPos.Val
          PA_KeSMSwAcsEntrySecRwRtStLgrstInwdOtwdPosMax_Val: accessed-parameter=KeSMSwAcsEntrySecRwRtStLgrstInwdOtwdPosMax.Val
          PA_KeSMSwAcsEntrySecRwRtStLgrstInwdOtwdPosMin_Val: accessed-parameter=KeSMSwAcsEntrySecRwRtStLgrstInwdOtwdPosMin.Val
          PA_KeSMSwAcsMd8SecRwRtStLgrstInwdOtwdPos_Val: accessed-parameter=KeSMSwAcsMd8SecRwRtStLgrstInwdOtwdPos.Val
          PA_KeSMSwAcsMd8SecRwRtStLgrstInwdOtwdPosMax_Val: accessed-parameter=KeSMSwAcsMd8SecRwRtStLgrstInwdOtwdPosMax.Val
          PA_KeSMSwAcsMd8SecRwRtStLgrstInwdOtwdPosMin_Val: accessed-parameter=KeSMSwAcsMd8SecRwRtStLgrstInwdOtwdPosMin.Val
          PA_KeSMSwAcsMd9SecRwRtStLgrstInwdOtwdPos_Val: accessed-parameter=KeSMSwAcsMd9SecRwRtStLgrstInwdOtwdPos.Val
          PA_KeSMSwAcsMd9SecRwRtStLgrstInwdOtwdPosMax_Val: accessed-parameter=KeSMSwAcsMd9SecRwRtStLgrstInwdOtwdPosMax.Val
          PA_KeSMSwAcsMd9SecRwRtStLgrstInwdOtwdPosMin_Val: accessed-parameter=KeSMSwAcsMd9SecRwRtStLgrstInwdOtwdPosMin.Val
          PA_KeSMSwRecoveryMdSecRwRtStLgrstInwdOtwdPos_Val: accessed-parameter=KeSMSwRecoveryMdSecRwRtStLgrstInwdOtwdPos.Val
          PA_KeSMSwRecoveryMdSecRwRtStLgrstInwdOtwdPosMax_Val: accessed-parameter=KeSMSwRecoveryMdSecRwRtStLgrstInwdOtwdPosMax.Val
          PA_KeSMSwRecoveryMdSecRwRtStLgrstInwdOtwdPosMin_Val: accessed-parameter=KeSMSwRecoveryMdSecRwRtStLgrstInwdOtwdPosMin.Val
          PA_KeSMSwVIPMdSecRwRtStLgrstInwdOtwdPos_Val: accessed-parameter=KeSMSwVIPMdSecRwRtStLgrstInwdOtwdPos.Val
          PA_KeSMSwVIPMdSecRwRtStLgrstInwdOtwdPosMax_Val: accessed-parameter=KeSMSwVIPMdSecRwRtStLgrstInwdOtwdPosMax.Val
          PA_KeSMSwVIPMdSecRwRtStLgrstInwdOtwdPosMin_Val: accessed-parameter=KeSMSwVIPMdSecRwRtStLgrstInwdOtwdPosMin.Val
        sync call SC_VIPR557TrgtPos_Get: operation=VIPR557TrgtPos.Get, timeout=0
        sync call SC_VIPRExit557TrgtPos_Get: operation=VIPRExit557TrgtPos.Get, timeout=0
      runnable SecRwRtStLgrstInwdOtwdTrgtPosSelc_Init
        99 x parameter access:
          PA_KeSMSw4SAcsMd24SecRwRtStLegrstOtwdInwdPos_Val: accessed-parameter=KeSMSw4SAcsMd24SecRwRtStLegrstOtwdInwdPos.Val
          PA_KeSMSw4SAcsMd24SecRwRtStLegrstOtwdInwdPosMax_Val: accessed-parameter=KeSMSw4SAcsMd24SecRwRtStLegrstOtwdInwdPosMax.Val
          PA_KeSMSw4SAcsMd24SecRwRtStLegrstOtwdInwdPosMin_Val: accessed-parameter=KeSMSw4SAcsMd24SecRwRtStLegrstOtwdInwdPosMin.Val
          PA_KeSMSw4SAcsMd26SecRwRtStLegrstOtwdInwdPos_Val: accessed-parameter=KeSMSw4SAcsMd26SecRwRtStLegrstOtwdInwdPos.Val
          PA_KeSMSw4SAcsMd26SecRwRtStLegrstOtwdInwdPosMax_Val: accessed-parameter=KeSMSw4SAcsMd26SecRwRtStLegrstOtwdInwdPosMax.Val
          PA_KeSMSw4SAcsMd26SecRwRtStLegrstOtwdInwdPosMin_Val: accessed-parameter=KeSMSw4SAcsMd26SecRwRtStLegrstOtwdInwdPosMin.Val
          PA_KeSMSw4SLegrstCloseMdSecRwRtStLgrstOtwdInwdPos_Val: accessed-parameter=KeSMSw4SLegrstCloseMdSecRwRtStLgrstOtwdInwdPos.Val
          PA_KeSMSw4SLegrstCloseMdSecRwRtStLgrstOtwdInwdPosMax_Val: accessed-parameter=KeSMSw4SLegrstCloseMdSecRwRtStLgrstOtwdInwdPosMax.Val
          PA_KeSMSw4SLegrstCloseMdSecRwRtStLgrstOtwdInwdPosMin_Val: accessed-parameter=KeSMSw4SLegrstCloseMdSecRwRtStLgrstOtwdInwdPosMin.Val
          PA_KeSMSw4SLegrstOpenMdSecRwRtStLgrstOtwdInwdPos_Val: accessed-parameter=KeSMSw4SLegrstOpenMdSecRwRtStLgrstOtwdInwdPos.Val
          PA_KeSMSw4SLegrstOpenMdSecRwRtStLgrstOtwdInwdPosMax_Val: accessed-parameter=KeSMSw4SLegrstOpenMdSecRwRtStLgrstOtwdInwdPosMax.Val
          PA_KeSMSw4SLegrstOpenMdSecRwRtStLgrstOtwdInwdPosMin_Val: accessed-parameter=KeSMSw4SLegrstOpenMdSecRwRtStLgrstOtwdInwdPosMin.Val
          PA_KeSMSw4sLyingMDSecRwRtStLgrstOtwdInwdPos_160_Val: accessed-parameter=KeSMSw4sLyingMDSecRwRtStLgrstOtwdInwdPos_160.Val
          PA_KeSMSw4sLyingMDSecRwRtStLgrstOtwdInwdPos_165_Val: accessed-parameter=KeSMSw4sLyingMDSecRwRtStLgrstOtwdInwdPos_165.Val
          PA_KeSMSw4sLyingMDSecRwRtStLgrstOtwdInwdPos_170_Val: accessed-parameter=KeSMSw4sLyingMDSecRwRtStLgrstOtwdInwdPos_170.Val
          PA_KeSMSw4sLyingMDSecRwRtStLgrstOtwdInwdPos_175_Val: accessed-parameter=KeSMSw4sLyingMDSecRwRtStLgrstOtwdInwdPos_175.Val
          PA_KeSMSw4sLyingMDSecRwRtStLgrstOtwdInwdPos_180_Val: accessed-parameter=KeSMSw4sLyingMDSecRwRtStLgrstOtwdInwdPos_180.Val
          PA_KeSMSw4sLyingMDSecRwRtStLgrstOtwdInwdPos_Below160_Val: accessed-parameter=KeSMSw4sLyingMDSecRwRtStLgrstOtwdInwdPos_Below160.Val
          PA_KeSMSw4sLyingMDSecRwRtStLgrstOtwdInwdPos_Over180_Val: accessed-parameter=KeSMSw4sLyingMDSecRwRtStLgrstOtwdInwdPos_Over180.Val
          PA_KeSMSw4sLyingMDSecRwRtStLgrstOtwdInwdPosMax_160_Val: accessed-parameter=KeSMSw4sLyingMDSecRwRtStLgrstOtwdInwdPosMax_160.Val
          PA_KeSMSw4sLyingMDSecRwRtStLgrstOtwdInwdPosMax_165_Val: accessed-parameter=KeSMSw4sLyingMDSecRwRtStLgrstOtwdInwdPosMax_165.Val
          PA_KeSMSw4sLyingMDSecRwRtStLgrstOtwdInwdPosMax_170_Val: accessed-parameter=KeSMSw4sLyingMDSecRwRtStLgrstOtwdInwdPosMax_170.Val
          PA_KeSMSw4sLyingMDSecRwRtStLgrstOtwdInwdPosMax_175_Val: accessed-parameter=KeSMSw4sLyingMDSecRwRtStLgrstOtwdInwdPosMax_175.Val
          PA_KeSMSw4sLyingMDSecRwRtStLgrstOtwdInwdPosMax_180_Val: accessed-parameter=KeSMSw4sLyingMDSecRwRtStLgrstOtwdInwdPosMax_180.Val
          PA_KeSMSw4sLyingMDSecRwRtStLgrstOtwdInwdPosMax_Below160_Val: accessed-parameter=KeSMSw4sLyingMDSecRwRtStLgrstOtwdInwdPosMax_Below160.Val
          PA_KeSMSw4sLyingMDSecRwRtStLgrstOtwdInwdPosMax_Over180_Val: accessed-parameter=KeSMSw4sLyingMDSecRwRtStLgrstOtwdInwdPosMax_Over180.Val
          PA_KeSMSw4sLyingMDSecRwRtStLgrstOtwdInwdPosMin_160_Val: accessed-parameter=KeSMSw4sLyingMDSecRwRtStLgrstOtwdInwdPosMin_160.Val
          PA_KeSMSw4sLyingMDSecRwRtStLgrstOtwdInwdPosMin_165_Val: accessed-parameter=KeSMSw4sLyingMDSecRwRtStLgrstOtwdInwdPosMin_165.Val
          PA_KeSMSw4sLyingMDSecRwRtStLgrstOtwdInwdPosMin_170_Val: accessed-parameter=KeSMSw4sLyingMDSecRwRtStLgrstOtwdInwdPosMin_170.Val
          PA_KeSMSw4sLyingMDSecRwRtStLgrstOtwdInwdPosMin_175_Val: accessed-parameter=KeSMSw4sLyingMDSecRwRtStLgrstOtwdInwdPosMin_175.Val
          PA_KeSMSw4sLyingMDSecRwRtStLgrstOtwdInwdPosMin_180_Val: accessed-parameter=KeSMSw4sLyingMDSecRwRtStLgrstOtwdInwdPosMin_180.Val
          PA_KeSMSw4sLyingMDSecRwRtStLgrstOtwdInwdPosMin_Below160_Val: accessed-parameter=KeSMSw4sLyingMDSecRwRtStLgrstOtwdInwdPosMin_Below160.Val
          PA_KeSMSw4sLyingMDSecRwRtStLgrstOtwdInwdPosMin_Over180_Val: accessed-parameter=KeSMSw4sLyingMDSecRwRtStLgrstOtwdInwdPosMin_Over180.Val
          PA_KeSMSw4sRecoveryMDSecRwRtStLgrstOtwdInwdPos_160_Val: accessed-parameter=KeSMSw4sRecoveryMDSecRwRtStLgrstOtwdInwdPos_160.Val
          PA_KeSMSw4sRecoveryMDSecRwRtStLgrstOtwdInwdPos_165_Val: accessed-parameter=KeSMSw4sRecoveryMDSecRwRtStLgrstOtwdInwdPos_165.Val
          PA_KeSMSw4sRecoveryMDSecRwRtStLgrstOtwdInwdPos_170_Val: accessed-parameter=KeSMSw4sRecoveryMDSecRwRtStLgrstOtwdInwdPos_170.Val
          PA_KeSMSw4sRecoveryMDSecRwRtStLgrstOtwdInwdPos_175_Val: accessed-parameter=KeSMSw4sRecoveryMDSecRwRtStLgrstOtwdInwdPos_175.Val
          PA_KeSMSw4sRecoveryMDSecRwRtStLgrstOtwdInwdPos_180_Val: accessed-parameter=KeSMSw4sRecoveryMDSecRwRtStLgrstOtwdInwdPos_180.Val
          PA_KeSMSw4sRecoveryMDSecRwRtStLgrstOtwdInwdPos_Below160_Val: accessed-parameter=KeSMSw4sRecoveryMDSecRwRtStLgrstOtwdInwdPos_Below160.Val
          PA_KeSMSw4sRecoveryMDSecRwRtStLgrstOtwdInwdPos_Over180_Val: accessed-parameter=KeSMSw4sRecoveryMDSecRwRtStLgrstOtwdInwdPos_Over180.Val
          PA_KeSMSw4sRecoveryMDSecRwRtStLgrstOtwdInwdPosMax_160_Val: accessed-parameter=KeSMSw4sRecoveryMDSecRwRtStLgrstOtwdInwdPosMax_160.Val
          PA_KeSMSw4sRecoveryMDSecRwRtStLgrstOtwdInwdPosMax_165_Val: accessed-parameter=KeSMSw4sRecoveryMDSecRwRtStLgrstOtwdInwdPosMax_165.Val
          PA_KeSMSw4sRecoveryMDSecRwRtStLgrstOtwdInwdPosMax_170_Val: accessed-parameter=KeSMSw4sRecoveryMDSecRwRtStLgrstOtwdInwdPosMax_170.Val
          PA_KeSMSw4sRecoveryMDSecRwRtStLgrstOtwdInwdPosMax_175_Val: accessed-parameter=KeSMSw4sRecoveryMDSecRwRtStLgrstOtwdInwdPosMax_175.Val
          PA_KeSMSw4sRecoveryMDSecRwRtStLgrstOtwdInwdPosMax_180_Val: accessed-parameter=KeSMSw4sRecoveryMDSecRwRtStLgrstOtwdInwdPosMax_180.Val
          PA_KeSMSw4sRecoveryMDSecRwRtStLgrstOtwdInwdPosMax_Below160_Val: accessed-parameter=KeSMSw4sRecoveryMDSecRwRtStLgrstOtwdInwdPosMax_Below160.Val
          PA_KeSMSw4sRecoveryMDSecRwRtStLgrstOtwdInwdPosMax_Over180_Val: accessed-parameter=KeSMSw4sRecoveryMDSecRwRtStLgrstOtwdInwdPosMax_Over180.Val
          PA_KeSMSw4sRecoveryMDSecRwRtStLgrstOtwdInwdPosMin_160_Val: accessed-parameter=KeSMSw4sRecoveryMDSecRwRtStLgrstOtwdInwdPosMin_160.Val
          PA_KeSMSw4sRecoveryMDSecRwRtStLgrstOtwdInwdPosMin_165_Val: accessed-parameter=KeSMSw4sRecoveryMDSecRwRtStLgrstOtwdInwdPosMin_165.Val
          PA_KeSMSw4sRecoveryMDSecRwRtStLgrstOtwdInwdPosMin_170_Val: accessed-parameter=KeSMSw4sRecoveryMDSecRwRtStLgrstOtwdInwdPosMin_170.Val
          PA_KeSMSw4sRecoveryMDSecRwRtStLgrstOtwdInwdPosMin_175_Val: accessed-parameter=KeSMSw4sRecoveryMDSecRwRtStLgrstOtwdInwdPosMin_175.Val
          PA_KeSMSw4sRecoveryMDSecRwRtStLgrstOtwdInwdPosMin_180_Val: accessed-parameter=KeSMSw4sRecoveryMDSecRwRtStLgrstOtwdInwdPosMin_180.Val
          PA_KeSMSw4sRecoveryMDSecRwRtStLgrstOtwdInwdPosMin_Below160_Val: accessed-parameter=KeSMSw4sRecoveryMDSecRwRtStLgrstOtwdInwdPosMin_Below160.Val
          PA_KeSMSw4sRecoveryMDSecRwRtStLgrstOtwdInwdPosMin_Over180_Val: accessed-parameter=KeSMSw4sRecoveryMDSecRwRtStLgrstOtwdInwdPosMin_Over180.Val
          PA_KeSMSw4sVIPMDSecRwRtStLgrstOtwdInwdPos_160_Val: accessed-parameter=KeSMSw4sVIPMDSecRwRtStLgrstOtwdInwdPos_160.Val
          PA_KeSMSw4sVIPMDSecRwRtStLgrstOtwdInwdPos_165_Val: accessed-parameter=KeSMSw4sVIPMDSecRwRtStLgrstOtwdInwdPos_165.Val
          PA_KeSMSw4sVIPMDSecRwRtStLgrstOtwdInwdPos_170_Val: accessed-parameter=KeSMSw4sVIPMDSecRwRtStLgrstOtwdInwdPos_170.Val
          PA_KeSMSw4sVIPMDSecRwRtStLgrstOtwdInwdPos_175_Val: accessed-parameter=KeSMSw4sVIPMDSecRwRtStLgrstOtwdInwdPos_175.Val
          PA_KeSMSw4sVIPMDSecRwRtStLgrstOtwdInwdPos_180_Val: accessed-parameter=KeSMSw4sVIPMDSecRwRtStLgrstOtwdInwdPos_180.Val
          PA_KeSMSw4sVIPMDSecRwRtStLgrstOtwdInwdPos_Below160_Val: accessed-parameter=KeSMSw4sVIPMDSecRwRtStLgrstOtwdInwdPos_Below160.Val
          PA_KeSMSw4sVIPMDSecRwRtStLgrstOtwdInwdPos_Over180_Val: accessed-parameter=KeSMSw4sVIPMDSecRwRtStLgrstOtwdInwdPos_Over180.Val
          PA_KeSMSw4sVIPMDSecRwRtStLgrstOtwdInwdPosMax_160_Val: accessed-parameter=KeSMSw4sVIPMDSecRwRtStLgrstOtwdInwdPosMax_160.Val
          PA_KeSMSw4sVIPMDSecRwRtStLgrstOtwdInwdPosMax_165_Val: accessed-parameter=KeSMSw4sVIPMDSecRwRtStLgrstOtwdInwdPosMax_165.Val
          PA_KeSMSw4sVIPMDSecRwRtStLgrstOtwdInwdPosMax_170_Val: accessed-parameter=KeSMSw4sVIPMDSecRwRtStLgrstOtwdInwdPosMax_170.Val
          PA_KeSMSw4sVIPMDSecRwRtStLgrstOtwdInwdPosMax_175_Val: accessed-parameter=KeSMSw4sVIPMDSecRwRtStLgrstOtwdInwdPosMax_175.Val
          PA_KeSMSw4sVIPMDSecRwRtStLgrstOtwdInwdPosMax_180_Val: accessed-parameter=KeSMSw4sVIPMDSecRwRtStLgrstOtwdInwdPosMax_180.Val
          PA_KeSMSw4sVIPMDSecRwRtStLgrstOtwdInwdPosMax_Below160_Val: accessed-parameter=KeSMSw4sVIPMDSecRwRtStLgrstOtwdInwdPosMax_Below160.Val
          PA_KeSMSw4sVIPMDSecRwRtStLgrstOtwdInwdPosMax_Over180_Val: accessed-parameter=KeSMSw4sVIPMDSecRwRtStLgrstOtwdInwdPosMax_Over180.Val
          PA_KeSMSw4sVIPMDSecRwRtStLgrstOtwdInwdPosMin_160_Val: accessed-parameter=KeSMSw4sVIPMDSecRwRtStLgrstOtwdInwdPosMin_160.Val
          PA_KeSMSw4sVIPMDSecRwRtStLgrstOtwdInwdPosMin_165_Val: accessed-parameter=KeSMSw4sVIPMDSecRwRtStLgrstOtwdInwdPosMin_165.Val
          PA_KeSMSw4sVIPMDSecRwRtStLgrstOtwdInwdPosMin_170_Val: accessed-parameter=KeSMSw4sVIPMDSecRwRtStLgrstOtwdInwdPosMin_170.Val
          PA_KeSMSw4sVIPMDSecRwRtStLgrstOtwdInwdPosMin_175_Val: accessed-parameter=KeSMSw4sVIPMDSecRwRtStLgrstOtwdInwdPosMin_175.Val
          PA_KeSMSw4sVIPMDSecRwRtStLgrstOtwdInwdPosMin_180_Val: accessed-parameter=KeSMSw4sVIPMDSecRwRtStLgrstOtwdInwdPosMin_180.Val
          PA_KeSMSw4sVIPMDSecRwRtStLgrstOtwdInwdPosMin_Below160_Val: accessed-parameter=KeSMSw4sVIPMDSecRwRtStLgrstOtwdInwdPosMin_Below160.Val
          PA_KeSMSw4sVIPMDSecRwRtStLgrstOtwdInwdPosMin_Over180_Val: accessed-parameter=KeSMSw4sVIPMDSecRwRtStLgrstOtwdInwdPosMin_Over180.Val
          PA_KeSMSw6sAcsEntrySecRwRtStLgrstInwdOtwdPos_Val: accessed-parameter=KeSMSw6sAcsEntrySecRwRtStLgrstInwdOtwdPos.Val
          PA_KeSMSw6sAcsEntrySecRwRtStLgrstInwdOtwdPosMax_Val: accessed-parameter=KeSMSw6sAcsEntrySecRwRtStLgrstInwdOtwdPosMax.Val
          PA_KeSMSw6sAcsEntrySecRwRtStLgrstInwdOtwdPosMin_Val: accessed-parameter=KeSMSw6sAcsEntrySecRwRtStLgrstInwdOtwdPosMin.Val
          PA_KeSMSw6sRecoveryMdSecRwRtStLgrstInwdOtwdPos_Val: accessed-parameter=KeSMSw6sRecoveryMdSecRwRtStLgrstInwdOtwdPos.Val
          PA_KeSMSw6sRecoveryMdSecRwRtStLgrstInwdOtwdPosMax_Val: accessed-parameter=KeSMSw6sRecoveryMdSecRwRtStLgrstInwdOtwdPosMax.Val
          PA_KeSMSw6sRecoveryMdSecRwRtStLgrstInwdOtwdPosMin_Val: accessed-parameter=KeSMSw6sRecoveryMdSecRwRtStLgrstInwdOtwdPosMin.Val
          PA_KeSMSw6SVIPMdSecRwRtStLgrstInwdOtwdPos_Val: accessed-parameter=KeSMSw6SVIPMdSecRwRtStLgrstInwdOtwdPos.Val
          PA_KeSMSw6SVIPMdSecRwRtStLgrstInwdOtwdPosMax_Val: accessed-parameter=KeSMSw6SVIPMdSecRwRtStLgrstInwdOtwdPosMax.Val
          PA_KeSMSw6SVIPMdSecRwRtStLgrstInwdOtwdPosMin_Val: accessed-parameter=KeSMSw6SVIPMdSecRwRtStLgrstInwdOtwdPosMin.Val
          PA_KeSMSwAcsEntrySecRwRtStLgrstInwdOtwdPos_Val: accessed-parameter=KeSMSwAcsEntrySecRwRtStLgrstInwdOtwdPos.Val
          PA_KeSMSwAcsEntrySecRwRtStLgrstInwdOtwdPosMax_Val: accessed-parameter=KeSMSwAcsEntrySecRwRtStLgrstInwdOtwdPosMax.Val
          PA_KeSMSwAcsEntrySecRwRtStLgrstInwdOtwdPosMin_Val: accessed-parameter=KeSMSwAcsEntrySecRwRtStLgrstInwdOtwdPosMin.Val
          PA_KeSMSwAcsMd8SecRwRtStLgrstInwdOtwdPos_Val: accessed-parameter=KeSMSwAcsMd8SecRwRtStLgrstInwdOtwdPos.Val
          PA_KeSMSwAcsMd8SecRwRtStLgrstInwdOtwdPosMax_Val: accessed-parameter=KeSMSwAcsMd8SecRwRtStLgrstInwdOtwdPosMax.Val
          PA_KeSMSwAcsMd8SecRwRtStLgrstInwdOtwdPosMin_Val: accessed-parameter=KeSMSwAcsMd8SecRwRtStLgrstInwdOtwdPosMin.Val
          PA_KeSMSwAcsMd9SecRwRtStLgrstInwdOtwdPos_Val: accessed-parameter=KeSMSwAcsMd9SecRwRtStLgrstInwdOtwdPos.Val
          PA_KeSMSwAcsMd9SecRwRtStLgrstInwdOtwdPosMax_Val: accessed-parameter=KeSMSwAcsMd9SecRwRtStLgrstInwdOtwdPosMax.Val
          PA_KeSMSwAcsMd9SecRwRtStLgrstInwdOtwdPosMin_Val: accessed-parameter=KeSMSwAcsMd9SecRwRtStLgrstInwdOtwdPosMin.Val
          PA_KeSMSwRecoveryMdSecRwRtStLgrstInwdOtwdPos_Val: accessed-parameter=KeSMSwRecoveryMdSecRwRtStLgrstInwdOtwdPos.Val
          PA_KeSMSwRecoveryMdSecRwRtStLgrstInwdOtwdPosMax_Val: accessed-parameter=KeSMSwRecoveryMdSecRwRtStLgrstInwdOtwdPosMax.Val
          PA_KeSMSwRecoveryMdSecRwRtStLgrstInwdOtwdPosMin_Val: accessed-parameter=KeSMSwRecoveryMdSecRwRtStLgrstInwdOtwdPosMin.Val
          PA_KeSMSwVIPMdSecRwRtStLgrstInwdOtwdPos_Val: accessed-parameter=KeSMSwVIPMdSecRwRtStLgrstInwdOtwdPos.Val
          PA_KeSMSwVIPMdSecRwRtStLgrstInwdOtwdPosMax_Val: accessed-parameter=KeSMSwVIPMdSecRwRtStLgrstInwdOtwdPosMax.Val
          PA_KeSMSwVIPMdSecRwRtStLgrstInwdOtwdPosMin_Val: accessed-parameter=KeSMSwVIPMdSecRwRtStLgrstInwdOtwdPosMin.Val
  swc implementation SecRwRtStLgrstInwdOtwdTrgtPosSelc_Implementation: behavior=SecRwRtStLgrstInwdOtwdTrgtPosSelc_InternalBehavior
    code-descriptors:
      code Default: artifact-descriptors=autosar-engineering-object={short-label=Default, category=SWSRC}
package /PATAC/MSM/ModeAdjust/CalPortInterface
  7 x parameter interface:
    KeSMSw4SAcsMd24SecRwRtStLegrstOtwdInwdPos
      parameter data prototype Val: sw-calibration-access=READ-WRITE, type=UInt16
    KeSMSw4SAcsMd24SecRwRtStLegrstOtwdInwdPosMax
      parameter data prototype Val: sw-calibration-access=READ-WRITE, type=UInt16
    KeSMSw4SAcsMd24SecRwRtStLegrstOtwdInwdPosMin
      parameter data prototype Val: sw-calibration-access=READ-WRITE, type=UInt16
    KeSMSw4SAcsMd26SecRwRtStLegrstOtwdInwdPos
      parameter data prototype Val: sw-calibration-access=READ-WRITE, type=UInt16
    KeSMSw4SAcsMd26SecRwRtStLegrstOtwdInwdPosMax
      parameter data prototype Val: sw-calibration-access=READ-WRITE, type=UInt16
    KeSMSw4SAcsMd26SecRwRtStLegrstOtwdInwdPosMin
      parameter data prototype Val: sw-calibration-access=READ-WRITE, type=UInt16
    Pos
      parameter data prototype Val: sw-calibration-access=READ-WRITE, type=UInt16
package /PATAC/MSM/ModeAdjust/DataType
  impl type TrgtPosCalibArray: category=ARRAY, sw-calibration-access=READ-ONLY, type-emitter=RTE  # 0:pos 1:max 2:min
    element Element: array-size=3, array-size-semantics=FIXED-SIZE, implementation-data-type=UInt16, invalid-value=0
package /PATAC/MSM/ModeAdjust/PortInterface
  client server interface SecRwRtStLgrstInwdOtwdTrgtPosSelc
    operation Cal
  client server interface VIPR557TrgtPos
    operation Get
      5 x arg, all with type=UInt16, direction=OUT, server-argument-impl-policy=USE-ARGUMENT-TYPE:
        SecRwLtStBkReclnTrgtPos
        SecRwLtStZeroTrgtPos
        SecRwLtStLgrstUpwdDnwdTrgtPos
        SecRwLtStLgrstInwdOtwdTrgtPos
        SecRwLtStFwdBkwdTrgtPos
    operation Set
      5 x arg, all with type=UInt16, direction=IN, server-argument-impl-policy=USE-ARGUMENT-TYPE:
        SecRwLtStBkReclnTrgtPos
        SecRwLtStZeroTrgtPos
        SecRwLtStLgrstUpwdDnwdTrgtPos
        SecRwLtStLgrstInwdOtwdTrgtPos
        SecRwLtStFwdBkwdTrgtPos
  client server interface VIPRExit557TrgtPos
    operation Get
      11 x arg, all with type=UInt16, direction=OUT, server-argument-impl-policy=USE-ARGUMENT-TYPE:
        SecRwRtStBkReclnTrgtPos
        SecRwRtStZeroTrgtPos
        SecRwRtStLgrstUpwdDnwdTrgtPos
        SecRwRtStLgrstInwdOtwdTrgtPos
        ThdRwLtStBkReclnTrgtPos
        ThdRwLtStFwdBkwdTrgtPos
        ThdRwRtStBkReclnTrgtPos
        ThdRwRtStFwdBkwdTrgtPos
        PassStBkReclnTrgtPos
        PassStFwdBkwdTrgtPos
        SecRwRtStFwdBkwdTrgtPos
    operation Set
  sender receiver interface HeightIndex: invalidation-policy{data-element=HeightIndex/Val, handle-invalid=DONT-INVALIDATE}
    data Val: type=UInt8  # 0：under 160 1：160 2：165 3：170 4：175 5：180 6：over 180
  sender receiver interface StNumFlg
    4 x data, all with type=Boolean:
      Is4s
      Is6s
      Is6s7s
      Is7s
    invalidation-policys:
      data-element=Is4s, handle-invalid=DONT-INVALIDATE
      data-element=Is6s, handle-invalid=DONT-INVALIDATE
      data-element=Is6s7s, handle-invalid=DONT-INVALIDATE
      data-element=Is7s, handle-invalid=DONT-INVALIDATE
  sender receiver interface TrgtPosCalibArray: invalidation-policy{data-element=TrgtPosArray, handle-invalid=DONT-INVALIDATE}
    data TrgtPosArray: type=TrgtPosCalibArray  # 0:Pos 1:Max 2:Min
package /PATAC/MSM/PortInterfaces
  sender receiver interface IfVeSMSbSecRwRtStCshnFrntUpwdDnwdMovConfig: invalidation-policy{data-element=IfVeSMSbSecRwRtStCshnFrntUpwdDnwdMovConfig/Val, handle-invalid=DONT-INVALIDATE}
    data Val: type=Boolean
